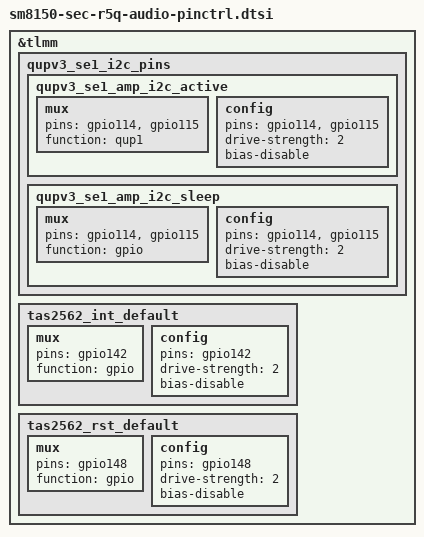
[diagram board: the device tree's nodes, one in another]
/* Copyright (c) 2016-2018, The Linux Foundation. All rights reserved.
 *
 * This program is free software; you can redistribute it and/or modify
 * it under the terms of the GNU General Public License version 2 and
 * only version 2 as published by the Free Software Foundation.
 *
 * This program is distributed in the hope that it will be useful,
 * but WITHOUT ANY WARRANTY; without even the implied warranty of
 * MERCHANTABILITY or FITNESS FOR A PARTICULAR PURPOSE.  See the
 * GNU General Public License for more details.
 */

&tlmm {
	/delete-node/ qupv3_se1_i2c_pins;
	qupv3_se1_i2c_pins: qupv3_se1_i2c_pins {
		qupv3_se1_amp_i2c_active: qupv3_se1_amp_i2c_active {
			mux {
				pins = "gpio114", "gpio115";
				function = "qup1";
			};
				config {
				pins = "gpio114", "gpio115";
				drive-strength = <2>;
				bias-disable;
			};
		};
		qupv3_se1_amp_i2c_sleep: qupv3_se1_amp_i2c_sleep {
			mux {
				pins = "gpio114", "gpio115";
				function = "gpio";
			};
				config {
				pins = "gpio114", "gpio115";
				drive-strength = <2>;
				bias-disable;
			};
		};
	};

	tas2562_int_default: tas2562_int_default {
		mux {
			pins = "gpio142";
			function = "gpio";
		};
		config {
			pins = "gpio142";
			drive-strength = <2>; /* 2 MA */
			bias-disable; /* No PULL */
		};
	};

	tas2562_rst_default: tas2562_rst_default {
		mux {
			pins = "gpio148";
			function = "gpio";
		};
		config {
			pins = "gpio148";
			drive-strength = <2>; /* 2 MA */
			bias-disable; /* No PULL */
		};
	};
};

